VERSION ""

NS_ :

BS_:

BU_: Engine Dashboard Transmission

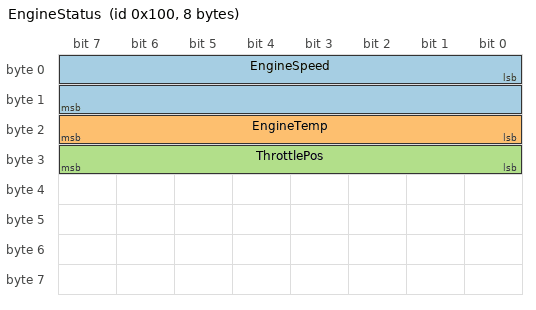
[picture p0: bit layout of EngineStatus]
BO_ 256 EngineStatus: 8 Engine
 SG_ EngineSpeed : 0|16@1+ (1,0) [0|8000] "rpm" Dashboard,Transmission
 SG_ EngineTemp : 16|8@1+ (1,-40) [-40|215] "degC" Dashboard
 SG_ ThrottlePos : 24|8@1+ (0.4,0) [0|100] "%" Transmission

BO_ 512 VehicleSpeed: 4 Transmission
 SG_ Speed : 0|16@1+ (0.01,0) [0|300] "km/h" Dashboard,Engine

BO_ 768 SystemState: 1 Dashboard
 SG_ IgnitionStatus : 0|2@1+ (1,0) [0|3] "" Engine,Transmission
